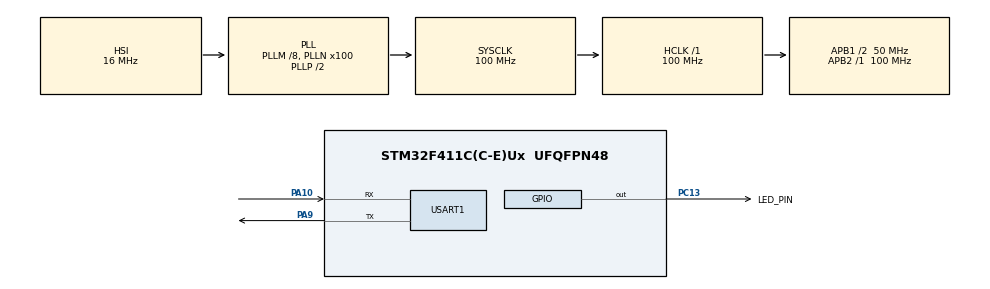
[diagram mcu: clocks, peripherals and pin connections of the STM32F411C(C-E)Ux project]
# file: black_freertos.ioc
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FREERTOS.Tasks01=defaultTask,24,128,StartDefaultTask,Default,NULL,Dynamic,NULL,NULL
FREERTOS.configUSE_NEWLIB_REENTRANT=1
Mcu.Family=STM32F4
Mcu.Name=STM32F411C(C-E)Ux
Mcu.Package=UFQFPN48
NVIC.PriorityGroup=NVIC_PRIORITYGROUP_4
NVIC.TIM1_UP_TIM10_IRQn=true\:15\:0\:false\:false\:true\:false\:false\:true\:true
NVIC.TimeBase=TIM1_UP_TIM10_IRQn
NVIC.TimeBaseIP=TIM1
PA10.Mode=Asynchronous
PA10.Signal=USART1_RX
PA9.Mode=Asynchronous
PA9.Signal=USART1_TX
PC13-ANTI_TAMP.GPIO_Label=LED_PIN
PC13-ANTI_TAMP.Signal=GPIO_Output
PH0\ -\ OSC_IN.Mode=HSE-External-Oscillator
PH0\ -\ OSC_IN.Signal=RCC_OSC_IN
PH1\ -\ OSC_OUT.Mode=HSE-External-Oscillator
PH1\ -\ OSC_OUT.Signal=RCC_OSC_OUT
ProjectManager.HeapSize=0x200
ProjectManager.StackSize=0x400
ProjectManager.TargetToolchain=Makefile
RCC.48MHZClocksFreq_Value=50000000
RCC.AHBFreq_Value=100000000
RCC.APB1CLKDivider=RCC_HCLK_DIV2
RCC.APB1Freq_Value=50000000
RCC.APB1TimFreq_Value=100000000
RCC.APB2Freq_Value=100000000
RCC.APB2TimFreq_Value=100000000
RCC.CortexFreq_Value=100000000
RCC.HCLKFreq_Value=100000000
RCC.HSE_VALUE=25000000
RCC.HSI_VALUE=16000000
RCC.LSE_VALUE=32768
RCC.PLLM=8
RCC.PLLN=100
RCC.SYSCLKFreq_VALUE=100000000
RCC.SYSCLKSource=RCC_SYSCLKSOURCE_PLLCLK
RCC.VCOOutputFreq_Value=200000000
USART1.VirtualMode=VM_ASYNC
VP_FREERTOS_VS_CMSIS_V2.Mode=CMSIS_V2
VP_SYS_VS_tim1.Mode=TIM1
board=custom

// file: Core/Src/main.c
/* USER CODE BEGIN Header */
/**
 ******************************************************************************
 * @file           : main.c
 * @brief          : Main program body
 ******************************************************************************
 * @attention
 *
 * Copyright (c) 2023 STMicroelectronics.
 * All rights reserved.
 *
 * This software is licensed under terms that can be found in the LICENSE file
 * in the root directory of this software component.
 * If no LICENSE file comes with this software, it is provided AS-IS.
 *
 ******************************************************************************
 */
#include "main.h"
UART_HandleTypeDef huart1;
#if 0
/* USER CODE END Header */
#include "cmsis_os.h"
#include "main.h"

/* USER CODE BEGIN Includes */
/* #include "FreeRTOS.h" */
/* #include "timers.h" */
/* USER CODE END Includes */

/* USER CODE BEGIN PD */
/* I just dont want to use cmsis: 2.0 stuff.The Idea is
   to run FreeRtos.
 */
#endif
/* USER CODE END PD */

/* USER CODE BEGIN PM */
#if 0
/* USER CODE END PM */

UART_HandleTypeDef huart1;

/* Definitions for defaultTask */
osThreadId_t defaultTaskHandle;
const osThreadAttr_t defaultTask_attributes = {
    .name       = "defaultTask",
    .stack_size = 128 * 4,
    .priority   = (osPriority_t)osPriorityNormal,
};
/* USER CODE BEGIN PV */
#endif
/* USER CODE END PV */

void SystemClock_Config(void);
static void MX_GPIO_Init(void);
static void MX_USART1_UART_Init(void);
void StartDefaultTask(void* argument);

int main(void)
{

    /* MCU Configuration--------------------------------------------------------*/

    /* Reset of all peripherals, Initializes the Flash interface and the Systick. */
    HAL_Init();

    /* Configure the system clock */
    SystemClock_Config();

    /* Initialize all configured peripherals */
    MX_GPIO_Init();
    MX_USART1_UART_Init();
    /* USER CODE BEGIN 2 */
#if 0
  /* USER CODE END 2 */

  /* Init scheduler */
  osKernelInitialize();

  /* Create the thread(s) */
  /* creation of defaultTask */
  defaultTaskHandle = osThreadNew(StartDefaultTask, NULL, &defaultTask_attributes);

  /* Start scheduler */
  osKernelStart();

  /* We should never get here as control is now taken by the scheduler */
  /* Infinite loop */
  /* USER CODE BEGIN WHILE */
#endif
    while (1)
    {
        extern void main_loop();
        main_loop();
        /* USER CODE END WHILE */

    }
}

void SystemClock_Config(void)
{
    RCC_OscInitTypeDef RCC_OscInitStruct = {0};
    RCC_ClkInitTypeDef RCC_ClkInitStruct = {0};

    /** Configure the main internal regulator output voltage
     */
    __HAL_RCC_PWR_CLK_ENABLE();
    __HAL_PWR_VOLTAGESCALING_CONFIG(PWR_REGULATOR_VOLTAGE_SCALE1);

    /** Initializes the RCC Oscillators according to the specified parameters
     * in the RCC_OscInitTypeDef structure.
     */
    RCC_OscInitStruct.OscillatorType      = RCC_OSCILLATORTYPE_HSI;
    RCC_OscInitStruct.HSIState            = RCC_HSI_ON;
    RCC_OscInitStruct.HSICalibrationValue = RCC_HSICALIBRATION_DEFAULT;
    RCC_OscInitStruct.PLL.PLLState        = RCC_PLL_ON;
    RCC_OscInitStruct.PLL.PLLSource       = RCC_PLLSOURCE_HSI;
    RCC_OscInitStruct.PLL.PLLM            = 8;
    RCC_OscInitStruct.PLL.PLLN            = 100;
    RCC_OscInitStruct.PLL.PLLP            = RCC_PLLP_DIV2;
    RCC_OscInitStruct.PLL.PLLQ            = 4;
    if (HAL_RCC_OscConfig(&RCC_OscInitStruct) != HAL_OK)
    {
        Error_Handler();
    }

    /** Initializes the CPU, AHB and APB buses clocks
     */
    RCC_ClkInitStruct.ClockType =
        RCC_CLOCKTYPE_HCLK | RCC_CLOCKTYPE_SYSCLK | RCC_CLOCKTYPE_PCLK1 | RCC_CLOCKTYPE_PCLK2;
    RCC_ClkInitStruct.SYSCLKSource   = RCC_SYSCLKSOURCE_PLLCLK;
    RCC_ClkInitStruct.AHBCLKDivider  = RCC_SYSCLK_DIV1;
    RCC_ClkInitStruct.APB1CLKDivider = RCC_HCLK_DIV2;
    RCC_ClkInitStruct.APB2CLKDivider = RCC_HCLK_DIV1;

    if (HAL_RCC_ClockConfig(&RCC_ClkInitStruct, FLASH_LATENCY_3) != HAL_OK)
    {
        Error_Handler();
    }
}

static void MX_USART1_UART_Init(void)
{

    huart1.Instance          = USART1;
    huart1.Init.BaudRate     = 115200;
    huart1.Init.WordLength   = UART_WORDLENGTH_8B;
    huart1.Init.StopBits     = UART_STOPBITS_1;
    huart1.Init.Parity       = UART_PARITY_NONE;
    huart1.Init.Mode         = UART_MODE_TX_RX;
    huart1.Init.HwFlowCtl    = UART_HWCONTROL_NONE;
    huart1.Init.OverSampling = UART_OVERSAMPLING_16;
    if (HAL_UART_Init(&huart1) != HAL_OK)
    {
        Error_Handler();
    }
}

static void MX_GPIO_Init(void)
{
    GPIO_InitTypeDef GPIO_InitStruct = {0};

    /* GPIO Ports Clock Enable */
    __HAL_RCC_GPIOC_CLK_ENABLE();
    __HAL_RCC_GPIOH_CLK_ENABLE();
    __HAL_RCC_GPIOA_CLK_ENABLE();

    /*Configure GPIO pin Output Level */
    HAL_GPIO_WritePin(LED_PIN_GPIO_Port, LED_PIN_Pin, GPIO_PIN_RESET);

    /*Configure GPIO pin : LED_PIN_Pin */
    GPIO_InitStruct.Pin   = LED_PIN_Pin;
    GPIO_InitStruct.Mode  = GPIO_MODE_OUTPUT_PP;
    GPIO_InitStruct.Pull  = GPIO_NOPULL;
    GPIO_InitStruct.Speed = GPIO_SPEED_FREQ_LOW;
    HAL_GPIO_Init(LED_PIN_GPIO_Port, &GPIO_InitStruct);

}

void StartDefaultTask(void* argument)
{
    /* USER CODE BEGIN 5 */
    /* Infinite loop */
    for (;;)
    {
        // osDelay(1);
    }
    /* USER CODE END 5 */
}

void HAL_TIM_PeriodElapsedCallback(TIM_HandleTypeDef* htim)
{
    if (htim->Instance == TIM1)
    {
        HAL_IncTick();
    }
}

void Error_Handler(void)
{
    /* USER CODE BEGIN Error_Handler_Debug */
    /* User can add his own implementation to report the HAL error return state */
    __disable_irq();
    while (1)
    {}
    /* USER CODE END Error_Handler_Debug */
}
